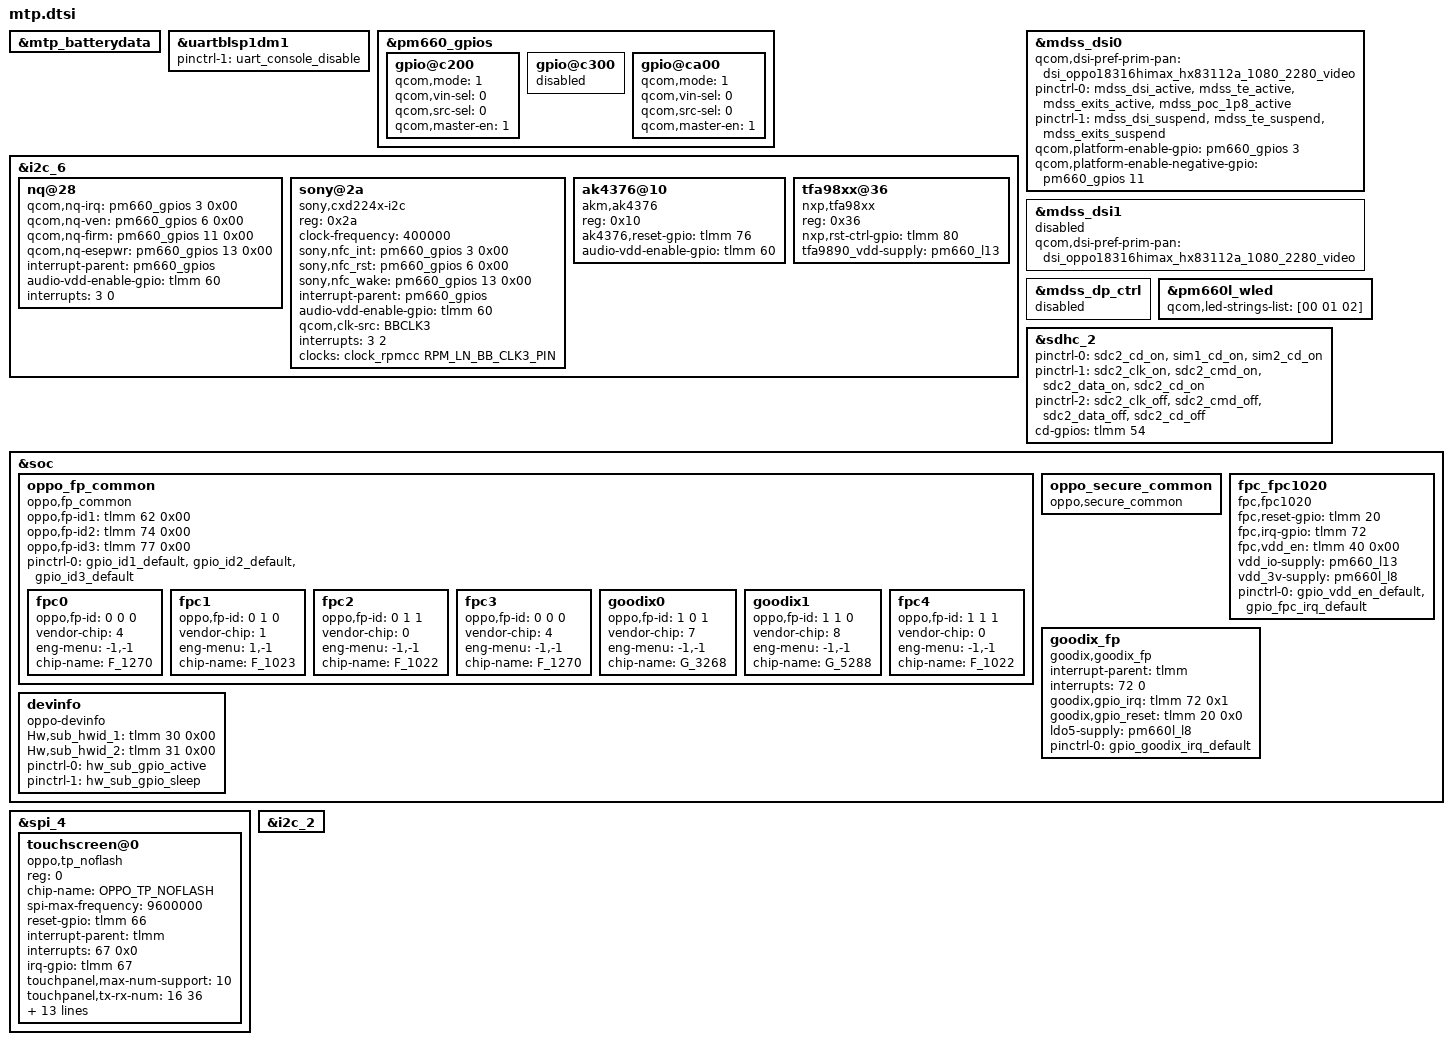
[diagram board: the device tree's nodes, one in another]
/* Copyright (c) 2019, The Linux Foundation. All rights reserved.
 *
 * This program is free software; you can redistribute it and/or modify
 * it under the terms of the GNU General Public License version 2 and
 * only version 2 as published by the Free Software Foundation.
 *
 * This program is distributed in the hope that it will be useful,
 * but WITHOUT ANY WARRANTY; without even the implied warranty of
 * MERCHANTABILITY or FITNESS FOR A PARTICULAR PURPOSE.  See the
 * GNU General Public License for more details.
 */

/* diff with sdm660-mtp.dtsi */
&mtp_batterydata{
    #include "fg-gen3-batterydata-atl-3000mah.dtsi"
};

&uartblsp1dm1 {
	pinctrl-names = "default", "disable";
	pinctrl-1 = <&uart_console_disable>;
};

&pm660_gpios {
    /* GPIO 3 for : +5v */
    gpio@c200 {
		qcom,mode = <1>;
		qcom,vin-sel = <0>;
		qcom,src-sel = <0>;
		qcom,master-en = <1>;
		status = "okay";
	};

	gpio@c300 {
		/delete-property/ qcom,mode;
        /delete-property/ qcom,vin-sel;
        /delete-property/ qcom,src-sel;
        /delete-property/ qcom,master-en;
		status = "disabled";
	};

	/* GPIO 11 for: -5v */
	gpio@ca00 {
		/delete-property/ qcom,pull;
		/delete-property/ qcom,out-strength;

		qcom,mode = <1>;
		qcom,vin-sel = <0>;
		qcom,src-sel = <0>;
		qcom,master-en = <1>;
		status = "okay";
	};
};

&i2c_6 {
    nq@28 {
		/delete-property/ pinctrl-names;
		/delete-property/ pinctrl-0;
		/delete-property/ pinctrl-1;

        qcom,nq-irq = <&pm660_gpios 3 0x00>;
		qcom,nq-ven = <&pm660_gpios 6 0x00>;
		qcom,nq-firm = <&pm660_gpios 11 0x00>;

        qcom,nq-esepwr = <&pm660_gpios 13 0x00>;
		interrupt-parent = <&pm660_gpios>;
		audio-vdd-enable-gpio = <&tlmm 60 0x00>;

        interrupts = <3 0>;
    };

    sony@2a {
		compatible = "sony,cxd224x-i2c";
		reg = <0x2a>;
		clock-frequency = <400000>;
		sony,nfc_int = <&pm660_gpios 3 0x00>;
		sony,nfc_rst = <&pm660_gpios 6 0x00>;
		sony,nfc_wake = <&pm660_gpios 13 0x00>;
		interrupt-parent = <&pm660_gpios>;
		audio-vdd-enable-gpio = <&tlmm 60 0x00>;
		qcom,clk-src = "BBCLK3";
		interrupts = <3 2>;/*1 = low-to-high edge triggered
                           2 = high-to-low edge triggered
                           4 = active high level-sensitive
                           8 = active low level-sensitive */
		interrupt-names = "nfc_irq";
		clocks = <&clock_rpmcc RPM_LN_BB_CLK3_PIN>;
		clock-names = "ref_clk";
	};
};

&mdss_dsi0 {
    qcom,dsi-pref-prim-pan = <&dsi_oppo18316himax_hx83112a_1080_2280_video>;
    pinctrl-0 = <&mdss_dsi_active &mdss_te_active &mdss_exits_active &mdss_poc_1p8_active>;
	pinctrl-1 = <&mdss_dsi_suspend &mdss_te_suspend &mdss_exits_suspend>;
    qcom,platform-enable-gpio = <&pm660_gpios 3 0>;              /* GPIO_01 LCD_5V_ENP */
	qcom,platform-enable-negative-gpio = <&pm660_gpios 11 0>;    /* GPIO_11 LCD_5V_ENN */
};

&mdss_dsi1 {
    status = "disabled";
    qcom,dsi-pref-prim-pan = <&dsi_oppo18316himax_hx83112a_1080_2280_video>;
};

&mdss_dp_ctrl {
    status = "disabled";
};

&pm660l_wled {
    qcom,led-strings-list = [00 01 02];
};

&sdhc_2 {
	pinctrl-names = "default", "active", "sleep";
	pinctrl-0 = <&sdc2_cd_on &sim1_cd_on &sim2_cd_on>;
	pinctrl-1 = <&sdc2_clk_on  &sdc2_cmd_on &sdc2_data_on &sdc2_cd_on>;
	pinctrl-2 = <&sdc2_clk_off &sdc2_cmd_off &sdc2_data_off &sdc2_cd_off>;
	cd-gpios = <&tlmm 54 0x0>;
};

&soc {
	oppo_fp_common {
		compatible = "oppo,fp_common"; //Manufacture, and Model
		
		oppo,fp-id1 = <&tlmm 62 0x00>;
		oppo,fp-id2 = <&tlmm 74 0x00>;
		oppo,fp-id3 = <&tlmm 77 0x00>;
		pinctrl-names = "default";
		pinctrl-0 = <&gpio_id1_default &gpio_id2_default &gpio_id3_default>;

		fpc0 {
			oppo,fp-id = <0 0 0>; /* fp id mapping table */
			vendor-chip = <4>; /* please refer to the struct fp_vendor_t in oppo_fp_commmon.h */
			eng-menu = "-1,-1"; /* represents SNR, inclination test item in engineer menu, and 0/1 means off/on */
			chip-name = "F_1270";  /* /proc/fp_id, will be displayed in engineer menu  */
		};

		fpc1 {
			oppo,fp-id = <0 1 0>; /* fp id mapping table */
			vendor-chip = <1>; /* please refer to the struct fp_vendor_t in oppo_fp_commmon.h */
			eng-menu = "1,-1"; /* represents SNR, inclination test item in engineer menu, and 0/1 means off/on */
			chip-name = "F_1023";  /* /proc/fp_id, will be displayed in engineer menu  */
		};

		fpc2 {
			oppo,fp-id = <0 1 1>; /* fp id mapping table */
			vendor-chip = <0>; /* please refer to the struct fp_vendor_t in oppo_fp_commmon.h */
			eng-menu = "-1,-1"; /* represents SNR, inclination test item in engineer menu, and 0/1 means off/on */
			chip-name = "F_1022";  /* /proc/fp_id, will be displayed in engineer menu  */
		};
	
		fpc3 {
			oppo,fp-id = <0 0 0>; /* fp id mapping table */
			vendor-chip = <4>; /* please refer to the struct fp_vendor_t in oppo_fp_commmon.h */
			eng-menu = "-1,-1"; /* represents SNR, inclination test item in engineer menu, and 0/1 means off/on */
			chip-name = "F_1270";  /* /proc/fp_id, will be displayed in engineer menu  */
		};

		goodix0 {
			oppo,fp-id = <1 0 1>; /* fp id mapping table */
			vendor-chip = <7>; /* please refer to the struct fp_vendor_t in oppo_fp_commmon.h */
			eng-menu = "-1,-1"; /* represents SNR, inclination test item in engineer menu, and 0/1 means off/on */
			chip-name = "G_3268";  /* /proc/fp_id, will be displayed in engineer menu  */
		};

		goodix1 {
			oppo,fp-id = <1 1 0>; /* fp id mapping table */
			vendor-chip = <8>; /* please refer to the struct fp_vendor_t in oppo_fp_commmon.h */
			eng-menu = "-1,-1"; /* represents SNR, inclination test item in engineer menu, and 0/1 means off/on */
			chip-name = "G_5288";  /* /proc/fp_id, will be displayed in engineer menu  */
		};

		fpc4 {
			oppo,fp-id = <1 1 1>; /* fp id mapping table */
			vendor-chip = <0>; /* please refer to the struct fp_vendor_t in oppo_fp_commmon.h */
			eng-menu = "-1,-1"; /* represents SNR, inclination test item in engineer menu, and 0/1 means off/on */
			chip-name = "F_1022";  /* /proc/fp_id, will be displayed in engineer menu  */
		};
	};

	oppo_secure_common { //Slave driver and CS ID
		compatible = "oppo,secure_common"; //Manufacture, and Model
	};

	fpc_fpc1020 { //Slave driver and CS ID
		compatible = "fpc,fpc1020"; //Manufacture, and Model
		fpc,reset-gpio = <&tlmm 20 0x00>;
		fpc,irq-gpio = <&tlmm 72 0x00>;
		fpc,vdd_en = <&tlmm 40 0x00>;
		vdd_io-supply = <&pm660_l13>;  // 1.8V
		vdd_3v-supply = <&pm660l_l8>;  // 3V
		pinctrl-names = "default";
		pinctrl-0 = <&gpio_vdd_en_default &gpio_fpc_irq_default>;
	};

    goodix_fp {
        compatible = "goodix,goodix_fp";
        interrupt-parent = <&tlmm>;
        interrupts = <72 0>;
        goodix,gpio_irq = <&tlmm 72 0x1>;
        goodix,gpio_reset = <&tlmm 20 0x0>;
        ldo5-supply = <&pm660l_l8>;  // pm660l_l8 for goodix_fp
        pinctrl-names = "default";
        pinctrl-0 = <&gpio_goodix_irq_default>;
    };

	devinfo {
		compatible = "oppo-devinfo";
		Hw,sub_hwid_1 = <&tlmm 30 0x00>;
		Hw,sub_hwid_2 = <&tlmm 31 0x00>;
		pinctrl-names = "default","hw_sub_gpio_sleep";
		pinctrl-0 = <&hw_sub_gpio_active>;
		pinctrl-1 = <&hw_sub_gpio_sleep>;
	};
};

&spi_4 {
	/* Novatek device tree node */
	status = "ok";
	touchscreen@0 {
		compatible = "oppo,tp_noflash";
		reg = <0>;
		chip-name = "OPPO_TP_NOFLASH";
		status = "ok";

		spi-max-frequency = <9600000>;	//4800000,9600000,15000000,19200000
		reset-gpio = <&tlmm 66 0x00>;
		interrupt-parent = <&tlmm>;
		interrupts = <67 0x0>;
		irq-gpio = <&tlmm 67 0x2002>;

		touchpanel,max-num-support = <10>;
		touchpanel,tx-rx-num = <16 36>;
		touchpanel,panel-coords = <1080 2340>;
		touchpanel,display-coords = <1080 2340>;

		incell_screen;
		fw_edge_limit_support;
		black_gesture_support;
		charger_pump_support;
		esd_handle_support;
		game_switch_support;
		black_gesture_test_support;
		noflash_support;
		smart_gesture_support;
		lcd_trigger_load_tp_fw_support;

		/*
		*Virtual Key Config:
		*1:touchpanel,button-type: <virtualkey_type  supportted_button-map>
		*virtualkey_type:
		*Type 1: using board_properties
		*Type 2: using same IC (button zone&& touch zone are seprate)
		*Type 3: using diffrent IC (button zone&& touch zone are seprate)
		*Type 4: No need of virtual key process
		*supportted_button-map:select|menu|home|back
		*
		*2:touchpanel,button-map
		*type (X1,Y1)(X2,Y2)(X3,Y3)(Width_X,Hight_Y)--Only when button-type is 0
		*/

		touchpanel,button-type = <4>;
	};
};

&i2c_2 {
	/delete-node/ smb1351-charger@1d;
};

&i2c_6 { /*  BLSP2 QUP2 */
	ak4376@10 {
		compatible = "akm,ak4376";
		reg = <0x10>;
		ak4376,reset-gpio = <&tlmm 76 0x00>;
		audio-vdd-enable-gpio = <&tlmm 60 0x00>;
		status = "okay";
	};

	tfa98xx@36 {
		compatible = "nxp,tfa98xx";
		reg = <0x36>;
		nxp,rst-ctrl-gpio = <&tlmm 80 0x00>;
		tfa9890_vdd-supply = <&pm660_l13>;
		status = "okay";
	};
};
